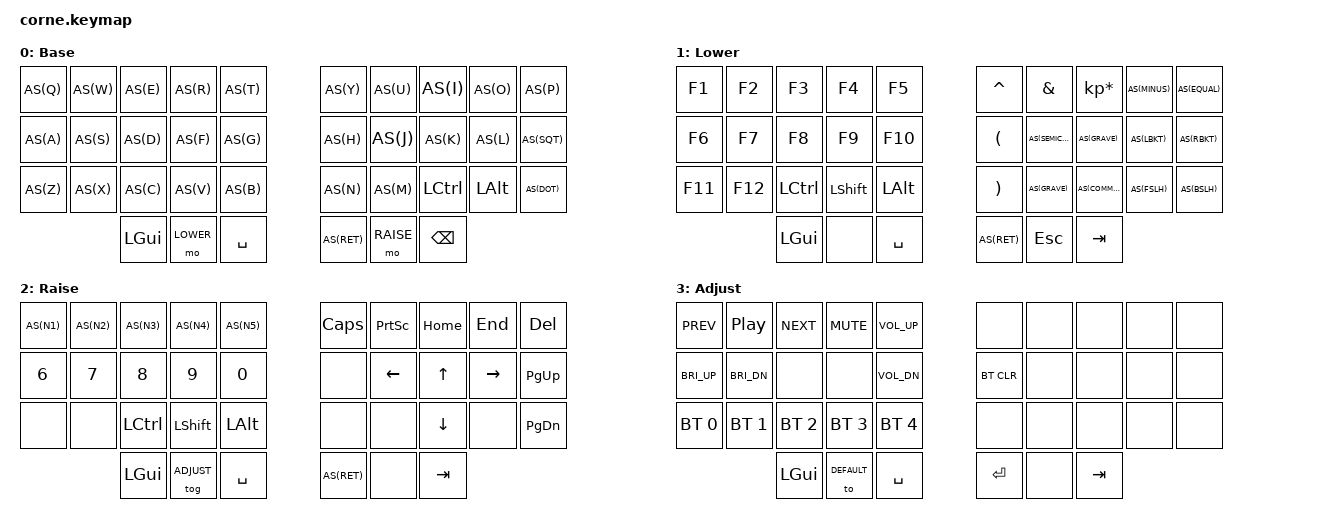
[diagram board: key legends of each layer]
/*
 * Copyright (c) 2020 The ZMK Contributors
 *
 * SPDX-License-Identifier: MIT
 */

#include <behaviors.dtsi>
#include <dt-bindings/zmk/keys.h>
#include <dt-bindings/zmk/bt.h>
#include <dt-bindings/zmk/outputs.h>

#define DEFAULT 0
#define LOWER   1
#define RAISE   2
#define ADJUST  3
#define AS(keycode) &as LS(keycode) keycode

/ {
    chosen {
        zmk,matrix_transform = &five_column_transform;
    };

    behaviors {
        as: auto_shift {
            compatible = "zmk,behavior-hold-tap";
            #binding-cells = <2>;
            tapping_term_ms = <300>;
            quick_tap_ms = <0>;
            flavor = "tap-preferred";
            bindings = <&kp>, <&kp>;
        };
    };
        
    keymap {
        compatible = "zmk,keymap";

        default_layer {
            // -----------------------------------------------------------------------------------------
            // |  Q  |  W  |  E  |  R  |  T  |   |  Y  |  U   |  I  |  O  |  P  |
            // |  A  |  S  |  D  |  F  |  G  |   |  H  |  J   |  K  |  L  |  '" |
            // |  Z  |  X  |  C  |  V  |  B  |   |  N  |  M   | CTRL| ALT |  .> |
            //             | GUI | LWR | SPC |   | ENT | RSE  | BSPC|
            display-name = "Base";
            bindings = <
                AS(Q) AS(W) AS(E) AS(R) AS(T)   AS(Y) AS(U) AS(I)     AS(O)    AS(P)
                AS(A) AS(S) AS(D) AS(F) AS(G)   AS(H) AS(J) AS(K)     AS(L)    AS(SQT)
                AS(Z) AS(X) AS(C) AS(V) AS(B)   AS(N) AS(M) &kp LCTL  &kp LALT AS(DOT)
                        &kp LGUI &mo LOWER &kp SPACE   AS(RET) &mo RAISE &kp BSPC
            >;
        };


        lower_layer {
            // -----------------------------------------------------------------------------------------
            // |  F1  |  F2  |  F3  |  F4  |  F5  |   |  ^  |  &  |  *  |  -_ |  =+ |
            // |  F6  |  F7  |  F8  |  F9  | F10  |   |  (  |  ;: |  `~ |  [{ |  ]} |
            // | F11  | F12  | CTRL | SHFT | ALT  |   |  )  |  `~ |  ,< |  /? |  \| |                         
            //                | GUI |      | SPC  |   | ENT | ESC | TAB |
            display-name = "Lower";
            bindings = <
                &kp F1   &kp F2   &kp F3   &kp F4     &kp F5      &kp CARET  &kp AMPS  &kp KP_MULTIPLY  AS(MINUS)  AS(EQUAL)
                &kp F6   &kp F7   &kp F8   &kp F9     &kp F10     &kp LPAR   AS(SEMICOLON) AS(GRAVE)        AS(LBKT)   AS(RBKT)
                &kp F11  &kp F12  &kp LCTL &kp LSHIFT &kp LALT    &kp RPAR   AS(GRAVE) AS(COMMA)        AS(FSLH)   AS(BSLH)
                                  &kp LGUI &none      &kp SPACE   AS(RET)    &kp ESC   &kp TAB
            >;
        };
    
        raise_layer {
            // -----------------------------------------------------------------------------------------
            // |  1!  |  2@  |  3#  |  4$  |  5%  |   | CAPS | PRNT | HOME | END  | DEL  |
            // |  6   |  7   |  8   |  9   |  0   |   |      | LEFT |  UP  | RIGHT| PGUP |
            // |      |      | CTRL | SHFT | ALT  |   |      |      | DOWN |      | PGDN |
            //                | GUI | ADJT | SPC  |   | ENT  |      | TAB  |
            display-name = "Raise";
            bindings = <
                AS(N1)    AS(N2)    AS(N3)    AS(N4)    AS(N5)      &kp CAPS  &kp PRINTSCREEN  &kp HOME  &kp END    &kp DEL
                &kp N6    &kp N7    &kp N8    &kp N9    &kp N0      &none     &kp LEFT         &kp UP    &kp RIGHT      &kp PG_UP
                &none     &none     &kp LCTL  &kp LSHIFT &kp LALT   &none     &none            &kp DOWN  &none  &kp PG_DN
                                    &kp LGUI  &tog ADJUST &kp SPACE AS(RET)   &none            &kp TAB
            >;
        };
        
        adjust_layer {
            // -----------------------------------------------------------------------------------------
            // | PREV | PLAY | NEXT | MUTE | VOL+ |   |     |     |     |     |     |
            // | BRI+ | BRI- |      |      | VOL- |   | BTCLR|    |     |     |     |
            // | BT0  | BT1  | BT2  | BT3  | BT4  |   |     |     |     |     |     |
            //                | GUI | BASE | SPC  |   | ENT |     | TAB |
            display-name = "Adjust";
            bindings = <
                &kp C_PREV    &kp C_PP      &kp C_NEXT    &kp C_MUTE    &kp C_VOL_UP    &none       &none           &none           &none           &none
                &kp C_BRI_UP  &kp C_BRI_DN  &none         &none         &kp C_VOL_DN    &bt BT_CLR  &none           &none           &none           &none
                &bt BT_SEL 0  &bt BT_SEL 1  &bt BT_SEL 2  &bt BT_SEL 3  &bt BT_SEL 4    &none       &none           &none           &none           &none
                                            &kp LGUI      &to DEFAULT   &kp SPACE       &kp RET     &none           &kp TAB
            >;
        };

        
    };
};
